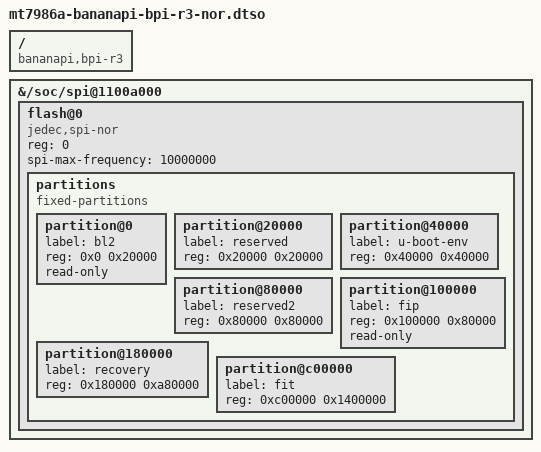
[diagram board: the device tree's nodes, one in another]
/* SPDX-License-Identifier: (GPL-2.0-only OR MIT) */
/*
 * Authors: Daniel Golle <daniel@makrotopia.org>
 *          Frank Wunderlich <frank-w@public-files.de>
 */

/dts-v1/;
/plugin/;

/ {
	compatible = "bananapi,bpi-r3", "mediatek,mt7986a";

	fragment@0 {
		target-path = "/soc/spi@1100a000";
		__overlay__ {
			#address-cells = <1>;
			#size-cells = <0>;
			flash@0 {
				compatible = "jedec,spi-nor";
				reg = <0>;
				spi-max-frequency = <10000000>;

				partitions {
					compatible = "fixed-partitions";
					#address-cells = <1>;
					#size-cells = <1>;

					partition@0 {
						label = "bl2";
						reg = <0x0 0x20000>;
						read-only;
					};

					partition@20000 {
						label = "reserved";
						reg = <0x20000 0x20000>;
					};

					partition@40000 {
						label = "u-boot-env";
						reg = <0x40000 0x40000>;
					};

					partition@80000 {
						label = "reserved2";
						reg = <0x80000 0x80000>;
					};

					partition@100000 {
						label = "fip";
						reg = <0x100000 0x80000>;
						read-only;
					};

					partition@180000 {
						label = "recovery";
						reg = <0x180000 0xa80000>;
					};

					partition@c00000 {
						label = "fit";
						reg = <0xc00000 0x1400000>;
					};
				};
			};
		};
	};
};
